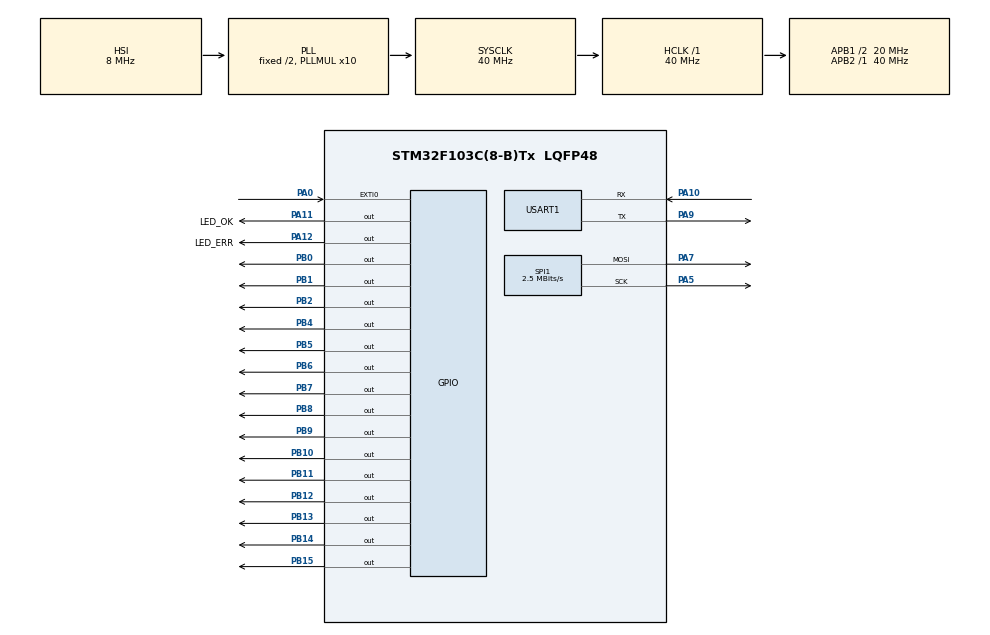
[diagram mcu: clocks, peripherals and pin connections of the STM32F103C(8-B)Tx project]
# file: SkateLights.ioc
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Dma.Request0=USART1_TX
Dma.Request1=SPI1_TX
Dma.SPI1_TX.1.Direction=DMA_MEMORY_TO_PERIPH
Dma.SPI1_TX.1.Instance=DMA1_Channel3
Dma.SPI1_TX.1.MemDataAlignment=DMA_MDATAALIGN_BYTE
Dma.SPI1_TX.1.MemInc=DMA_MINC_ENABLE
Dma.SPI1_TX.1.Mode=DMA_NORMAL
Dma.SPI1_TX.1.PeriphDataAlignment=DMA_PDATAALIGN_BYTE
Dma.SPI1_TX.1.PeriphInc=DMA_PINC_DISABLE
Dma.SPI1_TX.1.Priority=DMA_PRIORITY_LOW
Dma.USART1_TX.0.Direction=DMA_MEMORY_TO_PERIPH
Dma.USART1_TX.0.Instance=DMA1_Channel4
Dma.USART1_TX.0.MemDataAlignment=DMA_MDATAALIGN_BYTE
Dma.USART1_TX.0.MemInc=DMA_MINC_ENABLE
Dma.USART1_TX.0.Mode=DMA_NORMAL
Dma.USART1_TX.0.PeriphDataAlignment=DMA_PDATAALIGN_BYTE
Dma.USART1_TX.0.PeriphInc=DMA_PINC_DISABLE
Dma.USART1_TX.0.Priority=DMA_PRIORITY_MEDIUM
FREERTOS.BinarySemaphores01=neopixelDriverEnable,Dynamic,NULL;uartRxBufReady,Dynamic,NULL
FREERTOS.HEAP_NUMBER=4
FREERTOS.INCLUDE_eTaskGetState=1
FREERTOS.INCLUDE_pcTaskGetTaskName=1
FREERTOS.INCLUDE_vTaskCleanUpResources=1
FREERTOS.INCLUDE_vTaskDelayUntil=1
FREERTOS.INCLUDE_xQueueGetMutexHolder=1
FREERTOS.INCLUDE_xSemaphoreGetMutexHolder=1
FREERTOS.INCLUDE_xTaskAbortDelay=1
FREERTOS.INCLUDE_xTaskGetCurrentTaskHandle=1
FREERTOS.INCLUDE_xTaskGetHandle=1
FREERTOS.Mutexes01=pixelPreBufferMutex,Dynamic,NULL
FREERTOS.Queues01=UartSendQueue,4,uint32_t,0,Dynamic,NULL,NULL;wheelSpeedQueue,1,uint16_t,0,Dynamic,NULL,NULL
FREERTOS.Tasks01=defaultTask,-3,64,defaultTaskUnused,Default,NULL,Dynamic,NULL,NULL;uartSender,2,128,TaskUartSender,As external,NULL,Dynamic,NULL,NULL;neopixelDriver,0,256,TaskNeopixelDriver,As external,NULL,Dynamic,NULL,NULL;speedCalculator,0,128,TaskSpeedCalculator,As external,NULL,Dynamic,NULL,NULL
FREERTOS.configCHECK_FOR_STACK_OVERFLOW=0
FREERTOS.configENABLE_BACKWARD_COMPATIBILITY=0
FREERTOS.configGENERATE_RUN_TIME_STATS=1
FREERTOS.configIDLE_SHOULD_YIELD=0
FREERTOS.configLIBRARY_MAX_SYSCALL_INTERRUPT_PRIORITY=3
FREERTOS.configMINIMAL_STACK_SIZE=64
FREERTOS.configTIMER_QUEUE_LENGTH=4
FREERTOS.configTIMER_TASK_STACK_DEPTH=64
FREERTOS.configTOTAL_HEAP_SIZE=8096
FREERTOS.configUSE_TIMERS=1
FREERTOS.configUSE_TRACE_FACILITY=0
Mcu.Family=STM32F1
Mcu.Name=STM32F103C(8-B)Tx
Mcu.Package=LQFP48
NVIC.DMA1_Channel3_IRQn=true\:3\:0\:false\:false\:true\:true\:false\:true
NVIC.DMA1_Channel4_IRQn=true\:6\:0\:true\:false\:true\:true\:false\:true
NVIC.EXTI0_IRQn=true\:3\:0\:false\:false\:true\:true\:true\:true
NVIC.PriorityGroup=NVIC_PRIORITYGROUP_4
NVIC.SPI1_IRQn=true\:3\:0\:false\:false\:true\:true\:true\:true
NVIC.TIM1_UP_IRQn=true\:0\:0\:false\:false\:true\:false\:false\:true
NVIC.TIM3_IRQn=true\:3\:0\:false\:false\:true\:true\:true\:true
NVIC.TimeBase=TIM1_UP_IRQn
NVIC.TimeBaseIP=TIM1
PA0-WKUP.Signal=GPXTI0
PA10.Mode=Asynchronous
PA10.Signal=USART1_RX
PA11.GPIO_Label=LED_OK
PA11.Signal=GPIO_Output
PA12.GPIO_Label=LED_ERR
PA12.Signal=GPIO_Output
PA13.Mode=Trace_Asynchronous_SW
PA13.Signal=SYS_JTMS-SWDIO
PA14.Mode=Trace_Asynchronous_SW
PA14.Signal=SYS_JTCK-SWCLK
PA5.Mode=TX_Only_Simplex_Unidirect_Master
PA5.Signal=SPI1_SCK
PA7.Mode=TX_Only_Simplex_Unidirect_Master
PA7.Signal=SPI1_MOSI
PA9.Mode=Asynchronous
PA9.Signal=USART1_TX
PB0.Signal=GPIO_Output
PB1.Signal=GPIO_Output
PB10.Signal=GPIO_Output
PB11.Signal=GPIO_Output
PB12.Signal=GPIO_Output
PB13.Signal=GPIO_Output
PB14.Signal=GPIO_Output
PB15.Signal=GPIO_Output
PB2.Signal=GPIO_Output
PB3.Mode=Trace_Asynchronous_SW
PB3.Signal=SYS_JTDO-TRACESWO
PB4.GPIO_ModeDefaultOutputPP=GPIO_MODE_OUTPUT_PP
PB4.GPIO_PuPd=GPIO_PULLDOWN
PB4.GPIO_Speed=GPIO_SPEED_FREQ_LOW
PB4.PinState=GPIO_PIN_RESET
PB4.Signal=GPIO_Output
PB5.GPIO_ModeDefaultOutputPP=GPIO_MODE_OUTPUT_PP
PB5.GPIO_PuPd=GPIO_PULLDOWN
PB5.GPIO_Speed=GPIO_SPEED_FREQ_LOW
PB5.PinState=GPIO_PIN_RESET
PB5.Signal=GPIO_Output
PB6.GPIO_ModeDefaultOutputPP=GPIO_MODE_OUTPUT_PP
PB6.GPIO_PuPd=GPIO_PULLDOWN
PB6.GPIO_Speed=GPIO_SPEED_FREQ_LOW
PB6.PinState=GPIO_PIN_RESET
PB6.Signal=GPIO_Output
PB7.GPIO_ModeDefaultOutputPP=GPIO_MODE_OUTPUT_PP
PB7.GPIO_PuPd=GPIO_PULLDOWN
PB7.GPIO_Speed=GPIO_SPEED_FREQ_LOW
PB7.PinState=GPIO_PIN_RESET
PB7.Signal=GPIO_Output
PB8.GPIO_ModeDefaultOutputPP=GPIO_MODE_OUTPUT_PP
PB8.GPIO_PuPd=GPIO_PULLDOWN
PB8.GPIO_Speed=GPIO_SPEED_FREQ_LOW
PB8.PinState=GPIO_PIN_RESET
PB8.Signal=GPIO_Output
PB9.GPIO_ModeDefaultOutputPP=GPIO_MODE_OUTPUT_PP
PB9.GPIO_PuPd=GPIO_PULLDOWN
PB9.GPIO_Speed=GPIO_SPEED_FREQ_LOW
PB9.PinState=GPIO_PIN_RESET
PB9.Signal=GPIO_Output
ProjectManager.HeapSize=0x200
ProjectManager.StackSize=0x400
ProjectManager.TargetToolchain=TrueSTUDIO
RCC.AHBFreq_Value=40000000
RCC.APB1CLKDivider=RCC_HCLK_DIV2
RCC.APB1Freq_Value=20000000
RCC.APB1TimFreq_Value=40000000
RCC.APB2Freq_Value=40000000
RCC.APB2TimFreq_Value=40000000
RCC.HCLKFreq_Value=40000000
RCC.PLLMUL=RCC_PLL_MUL10
RCC.SYSCLKFreq_VALUE=40000000
RCC.SYSCLKSource=RCC_SYSCLKSOURCE_PLLCLK
RCC.USBFreq_Value=26666666.666666668
RCC.USBPrescaler=RCC_USBCLKSOURCE_PLL_DIV1_5
SPI1.BaudRatePrescaler=SPI_BAUDRATEPRESCALER_16
SPI1.CalculateBaudRate=2.5 MBits/s
SPI1.Direction=SPI_DIRECTION_2LINES
SPI1.Mode=SPI_MODE_MASTER
SPI1.VirtualType=VM_MASTER
TIM2.AutoReloadPreload=TIM_AUTORELOAD_PRELOAD_ENABLE
TIM2.Period=0xFFFF
TIM2.Prescaler=40000
TIM2.TIM_MasterOutputTrigger=TIM_TRGO_RESET
TIM3.AutoReloadPreload=TIM_AUTORELOAD_PRELOAD_DISABLE
TIM3.Period=1000
TIM3.Prescaler=3
USART1.Parity=PARITY_NONE
USART1.VirtualMode=VM_ASYNC
USART1.WordLength=WORDLENGTH_8B
VP_FREERTOS_VS_CMSIS_V1.Mode=CMSIS_V1
VP_SYS_VS_tim1.Mode=TIM1
VP_TIM2_VS_ClockSourceINT.Mode=Internal
VP_TIM3_VS_ClockSourceINT.Mode=Internal
board=custom

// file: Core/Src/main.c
/* USER CODE BEGIN Header */
/**
  ******************************************************************************
  * @file           : main.c
  * @brief          : Main program body
  ******************************************************************************
  * This notice applies to any and all portions of this file
  * that are not between comment pairs USER CODE BEGIN and
  * USER CODE END. Other portions of this file, whether
  * inserted by the user or by software development tools
  * are owned by their respective copyright owners.
  *
  * Copyright (c) 2018 STMicroelectronics International N.V.
  * All rights reserved.
  *
  * Redistribution and use in source and binary forms, with or without
  * modification, are permitted, provided that the following conditions are met:
  *
  * 1. Redistribution of source code must retain the above copyright notice,
  *    this list of conditions and the following disclaimer.
  * 2. Redistributions in binary form must reproduce the above copyright notice,
  *    this list of conditions and the following disclaimer in the documentation
  *    and/or other materials provided with the distribution.
  * 3. Neither the name of STMicroelectronics nor the names of other
  *    contributors to this software may be used to endorse or promote products
  *    derived from this software without specific written permission.
  * 4. This software, including modifications and/or derivative works of this
  *    software, must execute solely and exclusively on microcontroller or
  *    microprocessor devices manufactured by or for STMicroelectronics.
  * 5. Redistribution and use of this software other than as permitted under
  *    this license is void and will automatically terminate your rights under
  *    this license.
  *
  * THIS SOFTWARE IS PROVIDED BY STMICROELECTRONICS AND CONTRIBUTORS "AS IS"
  * AND ANY EXPRESS, IMPLIED OR STATUTORY WARRANTIES, INCLUDING, BUT NOT
  * LIMITED TO, THE IMPLIED WARRANTIES OF MERCHANTABILITY, FITNESS FOR A
  * PARTICULAR PURPOSE AND NON-INFRINGEMENT OF THIRD PARTY INTELLECTUAL PROPERTY
  * RIGHTS ARE DISCLAIMED TO THE FULLEST EXTENT PERMITTED BY LAW. IN NO EVENT
  * SHALL STMICROELECTRONICS OR CONTRIBUTORS BE LIABLE FOR ANY DIRECT, INDIRECT,
  * INCIDENTAL, SPECIAL, EXEMPLARY, OR CONSEQUENTIAL DAMAGES (INCLUDING, BUT NOT
  * LIMITED TO, PROCUREMENT OF SUBSTITUTE GOODS OR SERVICES; LOSS OF USE, DATA,
  * OR PROFITS; OR BUSINESS INTERRUPTION) HOWEVER CAUSED AND ON ANY THEORY OF
  * LIABILITY, WHETHER IN CONTRACT, STRICT LIABILITY, OR TORT (INCLUDING
  * NEGLIGENCE OR OTHERWISE) ARISING IN ANY WAY OUT OF THE USE OF THIS SOFTWARE,
  * EVEN IF ADVISED OF THE POSSIBILITY OF SUCH DAMAGE.
  *
  ******************************************************************************
  */
/* USER CODE END Header */

#include "main.h"
#include "cmsis_os.h"
#include "dma.h"
#include "spi.h"
#include "tim.h"
#include "usart.h"
#include "gpio.h"

void SystemClock_Config(void);
void MX_FREERTOS_Init(void);

int main(void)
{

  /* MCU Configuration--------------------------------------------------------*/

  /* Reset of all peripherals, Initializes the Flash interface and the Systick. */
  HAL_Init();

  /* Configure the system clock */
  SystemClock_Config();

  /* Initialize all configured peripherals */
  MX_GPIO_Init();
  MX_DMA_Init();
  MX_TIM2_Init();
  MX_TIM3_Init();
  MX_USART1_UART_Init();
  MX_SPI1_Init();

  /* Call init function for freertos objects (in freertos.c) */
  MX_FREERTOS_Init();

  /* Start scheduler */
  osKernelStart();

  /* We should never get here as control is now taken by the scheduler */

  /* Infinite loop */
  while (1)
  {

  }
}

void SystemClock_Config(void)
{
  RCC_OscInitTypeDef RCC_OscInitStruct = {0};
  RCC_ClkInitTypeDef RCC_ClkInitStruct = {0};

  /** Initializes the CPU, AHB and APB busses clocks
  */
  RCC_OscInitStruct.OscillatorType = RCC_OSCILLATORTYPE_HSI;
  RCC_OscInitStruct.HSIState = RCC_HSI_ON;
  RCC_OscInitStruct.HSICalibrationValue = RCC_HSICALIBRATION_DEFAULT;
  RCC_OscInitStruct.PLL.PLLState = RCC_PLL_ON;
  RCC_OscInitStruct.PLL.PLLSource = RCC_PLLSOURCE_HSI_DIV2;
  RCC_OscInitStruct.PLL.PLLMUL = RCC_PLL_MUL10;
  if (HAL_RCC_OscConfig(&RCC_OscInitStruct) != HAL_OK)
  {
    Error_Handler();
  }
  /** Initializes the CPU, AHB and APB busses clocks
  */
  RCC_ClkInitStruct.ClockType = RCC_CLOCKTYPE_HCLK|RCC_CLOCKTYPE_SYSCLK
                              |RCC_CLOCKTYPE_PCLK1|RCC_CLOCKTYPE_PCLK2;
  RCC_ClkInitStruct.SYSCLKSource = RCC_SYSCLKSOURCE_PLLCLK;
  RCC_ClkInitStruct.AHBCLKDivider = RCC_SYSCLK_DIV1;
  RCC_ClkInitStruct.APB1CLKDivider = RCC_HCLK_DIV2;
  RCC_ClkInitStruct.APB2CLKDivider = RCC_HCLK_DIV1;

  if (HAL_RCC_ClockConfig(&RCC_ClkInitStruct, FLASH_LATENCY_1) != HAL_OK)
  {
    Error_Handler();
  }
}

void HAL_TIM_PeriodElapsedCallback(TIM_HandleTypeDef *htim)
{
  if (htim->Instance == TIM1) {
    HAL_IncTick();
  }
}

void Error_Handler(void)
{
}

/************************ (C) COPYRIGHT STMicroelectronics *****END OF FILE****/

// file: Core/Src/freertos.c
/* USER CODE BEGIN Header */
/**
  ******************************************************************************
  * File Name          : freertos.c
  * Description        : Code for freertos applications
  ******************************************************************************
  * This notice applies to any and all portions of this file
  * that are not between comment pairs USER CODE BEGIN and
  * USER CODE END. Other portions of this file, whether
  * inserted by the user or by software development tools
  * are owned by their respective copyright owners.
  *
  * Copyright (c) 2018 STMicroelectronics International N.V.
  * All rights reserved.
  *
  * Redistribution and use in source and binary forms, with or without
  * modification, are permitted, provided that the following conditions are met:
  *
  * 1. Redistribution of source code must retain the above copyright notice,
  *    this list of conditions and the following disclaimer.
  * 2. Redistributions in binary form must reproduce the above copyright notice,
  *    this list of conditions and the following disclaimer in the documentation
  *    and/or other materials provided with the distribution.
  * 3. Neither the name of STMicroelectronics nor the names of other
  *    contributors to this software may be used to endorse or promote products
  *    derived from this software without specific written permission.
  * 4. This software, including modifications and/or derivative works of this
  *    software, must execute solely and exclusively on microcontroller or
  *    microprocessor devices manufactured by or for STMicroelectronics.
  * 5. Redistribution and use of this software other than as permitted under
  *    this license is void and will automatically terminate your rights under
  *    this license.
  *
  * THIS SOFTWARE IS PROVIDED BY STMICROELECTRONICS AND CONTRIBUTORS "AS IS"
  * AND ANY EXPRESS, IMPLIED OR STATUTORY WARRANTIES, INCLUDING, BUT NOT
  * LIMITED TO, THE IMPLIED WARRANTIES OF MERCHANTABILITY, FITNESS FOR A
  * PARTICULAR PURPOSE AND NON-INFRINGEMENT OF THIRD PARTY INTELLECTUAL PROPERTY
  * RIGHTS ARE DISCLAIMED TO THE FULLEST EXTENT PERMITTED BY LAW. IN NO EVENT
  * SHALL STMICROELECTRONICS OR CONTRIBUTORS BE LIABLE FOR ANY DIRECT, INDIRECT,
  * INCIDENTAL, SPECIAL, EXEMPLARY, OR CONSEQUENTIAL DAMAGES (INCLUDING, BUT NOT
  * LIMITED TO, PROCUREMENT OF SUBSTITUTE GOODS OR SERVICES; LOSS OF USE, DATA,
  * OR PROFITS; OR BUSINESS INTERRUPTION) HOWEVER CAUSED AND ON ANY THEORY OF
  * LIABILITY, WHETHER IN CONTRACT, STRICT LIABILITY, OR TORT (INCLUDING
  * NEGLIGENCE OR OTHERWISE) ARISING IN ANY WAY OUT OF THE USE OF THIS SOFTWARE,
  * EVEN IF ADVISED OF THE POSSIBILITY OF SUCH DAMAGE.
  *
  ******************************************************************************
  */
/* USER CODE END Header */

#include "FreeRTOS.h"
#include "task.h"
#include "main.h"
#include "cmsis_os.h"

/* USER CODE BEGIN Includes */
#include "applicationTasks.h"

/* USER CODE END Includes */

/* USER CODE BEGIN Variables */

// Memory pool to store strings to be printed over serial
osPoolId uartStrMemPoolHandle;

// Memory pool to contain buffer for the neopixels
osPoolId neopixelBufferPoolHandle;

/* USER CODE END Variables */
osThreadId defaultTaskHandle;
osThreadId uartSenderHandle;
osThreadId neopixelDriverHandle;
osThreadId speedCalculatorHandle;
osMessageQId UartSendQueueHandle;
osMessageQId wheelSpeedQueueHandle;
osMutexId pixelPreBufferMutexHandle;
osSemaphoreId neopixelDriverEnableHandle;
osSemaphoreId uartRxBufReadyHandle;

/* USER CODE BEGIN FunctionPrototypes */

osThreadId neopixelDickeryHandle;
osThreadId displaySpeedHandle;
/* USER CODE END FunctionPrototypes */

void defaultTaskUnused(void const * argument);
extern void TaskUartSender(void const * argument);
extern void TaskNeopixelDriver(void const * argument);
extern void TaskSpeedCalculator(void const * argument);
extern void TaskNeopixelDickery(void const * argument);
extern void TaskDisplaySpeed(void const * argument);

void MX_FREERTOS_Init(void); /* (MISRA C 2004 rule 8.1) */

/* Hook prototypes */
void configureTimerForRunTimeStats(void);
unsigned long getRunTimeCounterValue(void);

/* USER CODE BEGIN 1 */
/* Functions needed when configGENERATE_RUN_TIME_STATS is on */
__weak void configureTimerForRunTimeStats(void)
{

}

__weak unsigned long getRunTimeCounterValue(void)
{
return 0;
}
/* USER CODE END 1 */

void MX_FREERTOS_Init(void) {
  /* USER CODE BEGIN Init */

  osPoolDef(uartStrMemPool, 5, uint8_t[64]);
  uartStrMemPoolHandle = osPoolCreate(osPool(uartStrMemPool));

  // Initialize the memory pool for the neopixel buffer, and immediately allocate memory for it
  osPoolDef(neopixelBufferPool, 1, NeopixelArray_t);
  neopixelBufferPoolHandle = osPoolCreate(osPool(neopixelBufferPool));
  osPoolCAlloc(neopixelBufferPoolHandle);

  /* USER CODE END Init */

  /* Create the mutex(es) */
  /* definition and creation of pixelPreBufferMutex */
  osMutexDef(pixelPreBufferMutex);
  pixelPreBufferMutexHandle = osMutexCreate(osMutex(pixelPreBufferMutex));

  /* Create the semaphores(s) */
  /* definition and creation of neopixelDriverEnable */
  osSemaphoreDef(neopixelDriverEnable);
  neopixelDriverEnableHandle = osSemaphoreCreate(osSemaphore(neopixelDriverEnable), 1);

  /* definition and creation of uartRxBufReady */
  osSemaphoreDef(uartRxBufReady);
  uartRxBufReadyHandle = osSemaphoreCreate(osSemaphore(uartRxBufReady), 1);

  /* Create the queue(s) */
  /* definition and creation of UartSendQueue */
  osMessageQDef(UartSendQueue, 4, uint32_t);
  UartSendQueueHandle = osMessageCreate(osMessageQ(UartSendQueue), NULL);

  /* definition and creation of wheelSpeedQueue */
  osMessageQDef(wheelSpeedQueue, 1, uint16_t);
  wheelSpeedQueueHandle = osMessageCreate(osMessageQ(wheelSpeedQueue), NULL);

  /* Create the thread(s) */
  /* definition and creation of defaultTask */
  osThreadDef(defaultTask, defaultTaskUnused, osPriorityIdle, 0, 64);
  defaultTaskHandle = osThreadCreate(osThread(defaultTask), NULL);

  /* definition and creation of uartSender */
  osThreadDef(uartSender, TaskUartSender, osPriorityHigh, 0, 128);
  uartSenderHandle = osThreadCreate(osThread(uartSender), NULL);

  /* definition and creation of neopixelDriver */
  osThreadDef(neopixelDriver, TaskNeopixelDriver, osPriorityNormal, 0, 256);
  neopixelDriverHandle = osThreadCreate(osThread(neopixelDriver), NULL);

  /* definition and creation of speedCalculator */
  osThreadDef(speedCalculator, TaskSpeedCalculator, osPriorityNormal, 0, 128);
  speedCalculatorHandle = osThreadCreate(osThread(speedCalculator), NULL);

  /* USER CODE BEGIN RTOS_THREADS */
  /* add threads, ... */
  osThreadDef(neopixelDickery, TaskNeopixelDickery, osPriorityNormal, 0, 128);
  neopixelDickeryHandle = osThreadCreate(osThread(neopixelDickery), NULL);

  osThreadDef(displaySpeed, TaskDisplaySpeed, osPriorityNormal, 0, 64);
  displaySpeedHandle = osThreadCreate(osThread(displaySpeed), NULL);
  /* USER CODE END RTOS_THREADS */

}

void defaultTaskUnused(void const * argument)
{

  for(;;)
  {
    osDelay(1);
  }
}

/************************ (C) COPYRIGHT STMicroelectronics *****END OF FILE****/
